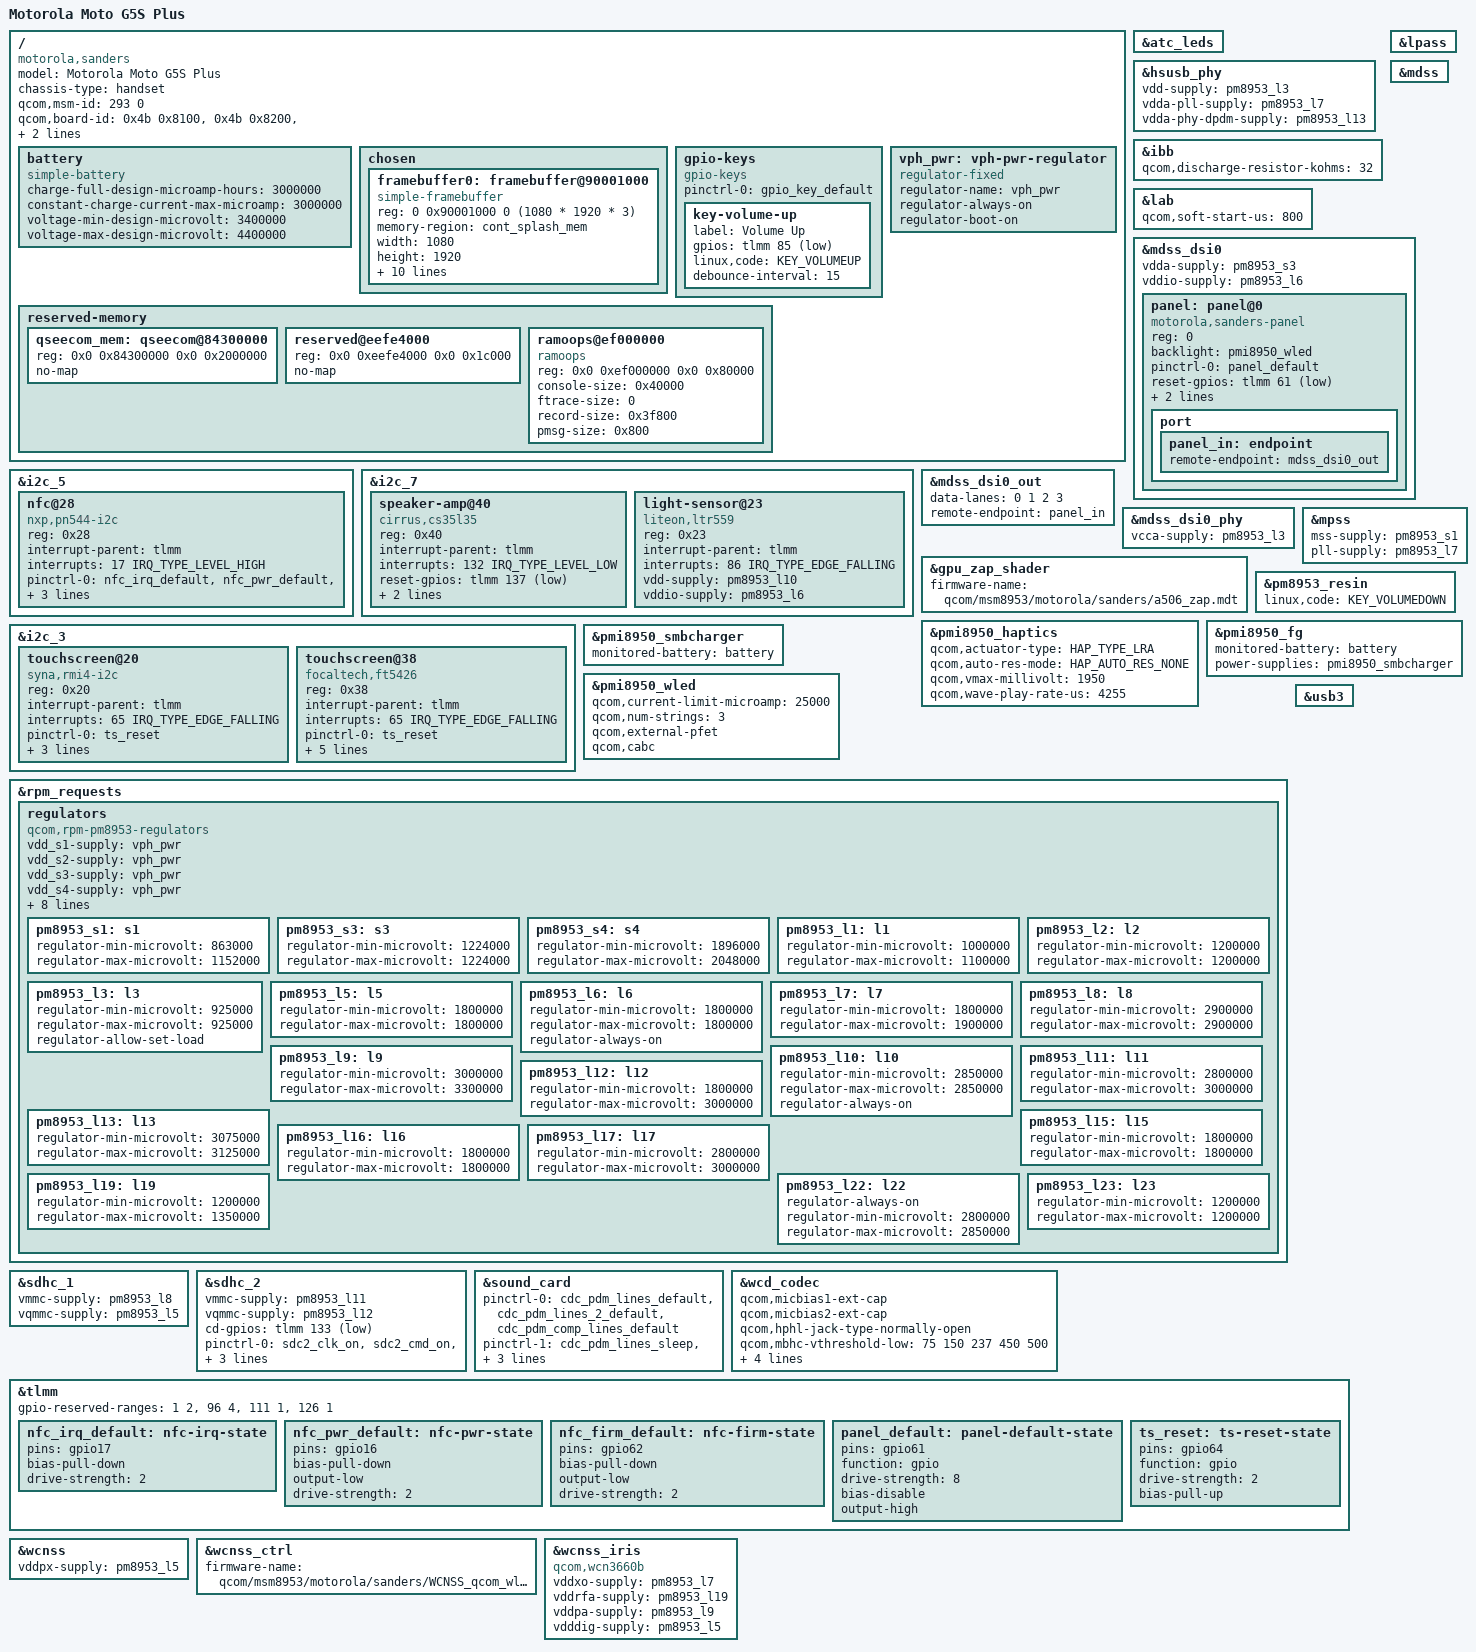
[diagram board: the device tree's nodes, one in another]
// SPDX-License-Identifier: BSD-3-Clause
/*
 * Copyright (c) 2022, Sireesh Kodali
 */
/dts-v1/;

#include "msm8953.dtsi"
#include "pm8953.dtsi"
#include "pmi8950.dtsi"

/delete-node/ &qseecom_mem;

/ {
	model = "Motorola Moto G5S Plus";
	compatible = "motorola,sanders", "qcom,msm8953";
	chassis-type = "handset";
	qcom,msm-id = <293 0>;
	qcom,board-id = <0x4b 0x8100>, <0x4b 0x8200>,
			<0x4b 0x8300>, <0x4b 0x83b0>,
			<0x4b 0x8400>, <0x4c 0x8400>;

	battery: battery {
		compatible = "simple-battery";

		charge-full-design-microamp-hours = <3000000>;
		constant-charge-current-max-microamp = <3000000>;
		voltage-min-design-microvolt = <3400000>;
		voltage-max-design-microvolt = <4400000>;
	};

	chosen {
		#address-cells = <2>;
		#size-cells = <2>;
		ranges;

		framebuffer0: framebuffer@90001000 {
			compatible = "simple-framebuffer";
			reg = <0 0x90001000 0 (1080 * 1920 * 3)>;
			memory-region = <&cont_splash_mem>;

			width = <1080>;
			height = <1920>;
			stride = <(1080 * 3)>;
			format = "r8g8b8";

			power-domains = <&gcc MDSS_GDSC>;

			clocks = <&gcc GCC_MDSS_AHB_CLK>,
				 <&gcc GCC_MDSS_AXI_CLK>,
				 <&gcc GCC_MDSS_VSYNC_CLK>,
				 <&gcc GCC_MDSS_MDP_CLK>,
				 <&gcc GCC_MDSS_BYTE0_CLK>,
				 <&gcc GCC_MDSS_PCLK0_CLK>,
				 <&gcc GCC_MDSS_ESC0_CLK>;
		};
	};

	gpio-keys {
		compatible = "gpio-keys";

		pinctrl-names = "default";
		pinctrl-0 = <&gpio_key_default>;

		key-volume-up {
			label = "Volume Up";
			gpios = <&tlmm 85 GPIO_ACTIVE_LOW>;
			linux,code = <KEY_VOLUMEUP>;
			debounce-interval = <15>;
		};
	};

	reserved-memory {
		qseecom_mem: qseecom@84300000 {
			reg = <0x0 0x84300000 0x0 0x2000000>;
			no-map;
		};

		reserved@eefe4000 {
			reg = <0x0 0xeefe4000 0x0 0x1c000>;
			no-map;
		};

		ramoops@ef000000 {
			compatible = "ramoops";
			reg = <0x0 0xef000000 0x0 0x80000>;
			console-size = <0x40000>;
			ftrace-size = <0>;
			record-size = <0x3f800>;
			pmsg-size = <0x800>;
		};
	};

	vph_pwr: vph-pwr-regulator {
		compatible = "regulator-fixed";
		regulator-name = "vph_pwr";
		regulator-always-on;
		regulator-boot-on;
	};
};

&i2c_5 {
	status = "okay";

	nfc@28 {
		compatible = "nxp,pn544-i2c";
		reg = <0x28>;

		interrupt-parent = <&tlmm>;
		interrupts = <17 IRQ_TYPE_LEVEL_HIGH>;

		pinctrl-names = "default";
		pinctrl-0 = <&nfc_irq_default &nfc_pwr_default &nfc_firm_default>;

		enable-gpios = <&tlmm 16 GPIO_ACTIVE_HIGH>;
		firmware-gpios = <&tlmm 62 GPIO_ACTIVE_HIGH>;
	};
};

&i2c_7 {
	status = "okay";

	speaker-amp@40 {
		compatible = "cirrus,cs35l35";
		reg = <0x40>;

		interrupt-parent = <&tlmm>;
		interrupts = <132 IRQ_TYPE_LEVEL_LOW>;

		reset-gpios = <&tlmm 137 GPIO_ACTIVE_LOW>;

		VA-supply = <&vph_pwr>;
		VP-supply = <&vph_pwr>;
	};

	light-sensor@23 {
		compatible = "liteon,ltr559";
		reg = <0x23>;

		interrupt-parent = <&tlmm>;
		interrupts = <86 IRQ_TYPE_EDGE_FALLING>;

		vdd-supply = <&pm8953_l10>;
		vddio-supply = <&pm8953_l6>;
	};
};

&atc_leds {
	status = "okay";
};

&hsusb_phy {
	vdd-supply = <&pm8953_l3>;
	vdda-pll-supply = <&pm8953_l7>;
	vdda-phy-dpdm-supply = <&pm8953_l13>;

	status = "okay";
};

&i2c_3 {
	status = "okay";

	touchscreen@20 {
		compatible = "syna,rmi4-i2c";
		reg = <0x20>;

		interrupt-parent = <&tlmm>;
		interrupts = <65 IRQ_TYPE_EDGE_FALLING>;

		pinctrl-names = "default";
		pinctrl-0 = <&ts_reset>;

		reset-gpios = <&tlmm 64 GPIO_ACTIVE_LOW>;

		vdd-supply = <&pm8953_l22>;
		vio-supply = <&pm8953_l6>;
	};

	touchscreen@38 {
		compatible = "focaltech,ft5426";
		reg = <0x38>;

		interrupt-parent = <&tlmm>;
		interrupts = <65 IRQ_TYPE_EDGE_FALLING>;

		pinctrl-names = "default";
		pinctrl-0 = <&ts_reset>;

		reset-gpios = <&tlmm 64 GPIO_ACTIVE_LOW>;

		vcc-supply = <&pm8953_l10>;
		iovcc-supply = <&pm8953_l5>;

		touchscreen-size-x = <1080>;
		touchscreen-size-y = <1920>;
	};
};

&ibb {
	qcom,discharge-resistor-kohms = <32>;
};

&lab {
	qcom,soft-start-us = <800>;
};

&lpass {
	status = "okay";
};

&mdss {
	status = "okay";
};

&mdss_dsi0 {
	status = "okay";

	vdda-supply = <&pm8953_s3>;
	vddio-supply = <&pm8953_l6>;

	panel: panel@0 {
		compatible = "motorola,sanders-panel";
		reg = <0>;

		backlight = <&pmi8950_wled>;

		pinctrl-names = "default";
		pinctrl-0 = <&panel_default>;

		reset-gpios = <&tlmm 61 GPIO_ACTIVE_LOW>;

		vsp-supply = <&lab>;
		vsn-supply = <&ibb>;

		port {
			panel_in: endpoint {
				remote-endpoint = <&mdss_dsi0_out>;
			};
		};
	};
};

&mdss_dsi0_out {
	data-lanes = <0 1 2 3>;
	remote-endpoint = <&panel_in>;
};

&mdss_dsi0_phy {
	vcca-supply = <&pm8953_l3>;

	status = "okay";
};

&mpss {
	status = "okay";

	mss-supply = <&pm8953_s1>;
	pll-supply = <&pm8953_l7>;
};

&gpu_zap_shader {
	firmware-name = "qcom/msm8953/motorola/sanders/a506_zap.mdt";
};

&pm8953_resin {
	linux,code = <KEY_VOLUMEDOWN>;
	status = "okay";
};

&pmi8950_haptics {
	qcom,actuator-type = <HAP_TYPE_LRA>;
	qcom,auto-res-mode = <HAP_AUTO_RES_NONE>;
	qcom,vmax-millivolt = <1950>;
	qcom,wave-play-rate-us = <4255>;

	status = "okay";
};

&pmi8950_fg {
	monitored-battery = <&battery>;
	power-supplies = <&pmi8950_smbcharger>;
	status = "okay";
};

&pmi8950_smbcharger {
	monitored-battery = <&battery>;
	status = "okay";
};

&pmi8950_wled {
	qcom,current-limit-microamp = <25000>;
	qcom,num-strings = <3>;
	qcom,external-pfet;
	qcom,cabc;

	status = "okay";
};

&rpm_requests {
	regulators {
		compatible = "qcom,rpm-pm8953-regulators";
		vdd_s1-supply = <&vph_pwr>;
		vdd_s2-supply = <&vph_pwr>;
		vdd_s3-supply = <&vph_pwr>;
		vdd_s4-supply = <&vph_pwr>;
		vdd_s5-supply = <&vph_pwr>;
		vdd_s6-supply = <&vph_pwr>;
		vdd_s7-supply = <&vph_pwr>;
		vdd_l1-supply = <&pm8953_s3>;
		vdd_l2_l3-supply = <&pm8953_s3>;
		vdd_l4_l5_l6_l7_l16_l19-supply = <&pm8953_s4>;
		vdd_l8_l11_l12_l13_l14_l15-supply = <&vph_pwr>;
		vdd_l9_l10_l17_l18_l22-supply = <&vph_pwr>;

		pm8953_s1: s1 {
			regulator-min-microvolt = <863000>;
			regulator-max-microvolt = <1152000>;
		};

		pm8953_s3: s3 {
			regulator-min-microvolt = <1224000>;
			regulator-max-microvolt = <1224000>;
		};

		pm8953_s4: s4 {
			regulator-min-microvolt = <1896000>;
			regulator-max-microvolt = <2048000>;
		};

		pm8953_l1: l1 {
			regulator-min-microvolt = <1000000>;
			regulator-max-microvolt = <1100000>;
		};

		pm8953_l2: l2 {
			regulator-min-microvolt = <1200000>;
			regulator-max-microvolt = <1200000>;
		};

		pm8953_l3: l3 {
			regulator-min-microvolt = <925000>;
			regulator-max-microvolt = <925000>;
			regulator-allow-set-load;
		};

		pm8953_l5: l5 {
			regulator-min-microvolt = <1800000>;
			regulator-max-microvolt = <1800000>;
		};

		pm8953_l6: l6 {
			regulator-min-microvolt = <1800000>;
			regulator-max-microvolt = <1800000>;
			regulator-always-on;
		};

		pm8953_l7: l7 {
			regulator-min-microvolt = <1800000>;
			regulator-max-microvolt = <1900000>;
		};

		pm8953_l8: l8 {
			regulator-min-microvolt = <2900000>;
			regulator-max-microvolt = <2900000>;
		};

		pm8953_l9: l9 {
			regulator-min-microvolt = <3000000>;
			regulator-max-microvolt = <3300000>;
		};

		pm8953_l10: l10 {
			regulator-min-microvolt = <2850000>;
			regulator-max-microvolt = <2850000>;
			regulator-always-on;
		};

		pm8953_l11: l11 {
			regulator-min-microvolt = <2800000>;
			regulator-max-microvolt = <3000000>;
		};

		pm8953_l12: l12 {
			regulator-min-microvolt = <1800000>;
			regulator-max-microvolt = <3000000>;
		};

		pm8953_l13: l13 {
			regulator-min-microvolt = <3075000>;
			regulator-max-microvolt = <3125000>;
		};

		pm8953_l15: l15 {
			regulator-min-microvolt = <1800000>;
			regulator-max-microvolt = <1800000>;
		};

		pm8953_l16: l16 {
			regulator-min-microvolt = <1800000>;
			regulator-max-microvolt = <1800000>;
		};

		pm8953_l17: l17 {
			regulator-min-microvolt = <2800000>;
			regulator-max-microvolt = <3000000>;
		};

		pm8953_l19: l19 {
			regulator-min-microvolt = <1200000>;
			regulator-max-microvolt = <1350000>;
		};

		pm8953_l22: l22 {
			regulator-always-on;
			regulator-min-microvolt = <2800000>;
			regulator-max-microvolt = <2850000>;
		};

		pm8953_l23: l23 {
			regulator-min-microvolt = <1200000>;
			regulator-max-microvolt = <1200000>;
		};
	};
};

&sdhc_1 {
	vmmc-supply = <&pm8953_l8>;
	vqmmc-supply = <&pm8953_l5>;

	status = "okay";
};

&sdhc_2 {
	vmmc-supply = <&pm8953_l11>;
	vqmmc-supply = <&pm8953_l12>;

	cd-gpios = <&tlmm 133 GPIO_ACTIVE_LOW>;

	pinctrl-names = "default", "sleep";
	pinctrl-0 = <&sdc2_clk_on &sdc2_cmd_on &sdc2_data_on &sdc2_cd_off>;
	pinctrl-1 = <&sdc2_clk_off &sdc2_cmd_off &sdc2_data_off &sdc2_cd_off>;

	status = "okay";
};

&usb3 {
	status = "okay";
};

&sound_card {
	status = "okay";

	pinctrl-names = "default", "sleep";
	pinctrl-0 = <&cdc_pdm_lines_default &cdc_pdm_lines_2_default &cdc_pdm_comp_lines_default>;
	pinctrl-1 = <&cdc_pdm_lines_sleep &cdc_pdm_lines_2_sleep &cdc_pdm_comp_lines_sleep>;

	model = "motorola-sanders";
};

&wcd_codec {
	status = "okay";

	qcom,micbias1-ext-cap;
	qcom,micbias2-ext-cap;
	qcom,hphl-jack-type-normally-open;
	qcom,mbhc-vthreshold-low = <75 150 237 450 500>;
	qcom,mbhc-vthreshold-high = <75 150 237 450 500>;

	vdd-cdc-io-supply = <&pm8953_l5>;
	vdd-cdc-tx-rx-cx-supply = <&pm8953_s4>;
	vdd-micbias-supply = <&pm8953_l13>;
};

&tlmm {
	gpio-reserved-ranges = <1 2>, <96 4>, <111 1>, <126 1>;

	nfc_irq_default: nfc-irq-state {
		pins = "gpio17";
		bias-pull-down;
		drive-strength = <2>;
	};

	nfc_pwr_default: nfc-pwr-state {
		pins = "gpio16";
		bias-pull-down;
		output-low;
		drive-strength = <2>;
	};

	nfc_firm_default: nfc-firm-state {
		pins = "gpio62";
		bias-pull-down;
		output-low;
		drive-strength = <2>;
	};

	panel_default: panel-default-state {
		pins = "gpio61";
		function = "gpio";
		drive-strength = <8>;
		bias-disable;
		output-high;
	};

	ts_reset: ts-reset-state {
		pins = "gpio64";
		function = "gpio";
		drive-strength = <2>;
		bias-pull-up;
	};
};

&wcnss {
	status = "okay";
	vddpx-supply = <&pm8953_l5>;
};

&wcnss_ctrl {
	firmware-name = "qcom/msm8953/motorola/sanders/WCNSS_qcom_wlan_nv.bin";
};

&wcnss_iris {
	compatible = "qcom,wcn3660b";

	vddxo-supply = <&pm8953_l7>;
	vddrfa-supply = <&pm8953_l19>;
	vddpa-supply = <&pm8953_l9>;
	vdddig-supply = <&pm8953_l5>;
};
